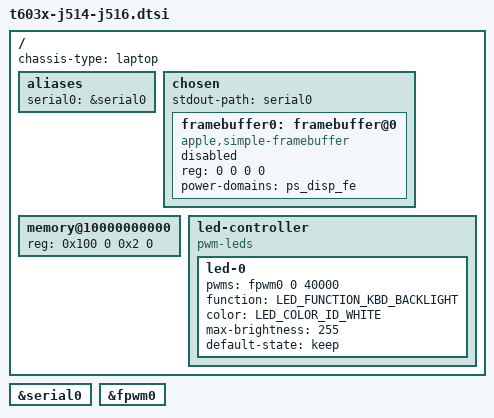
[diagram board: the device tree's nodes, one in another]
// SPDX-License-Identifier: GPL-2.0+ OR MIT
/*
 * MacBook Pro (14/16-inch, 2023)
 *
 * This file contains the parts common to J514 and J516 devices with t6030,
 * t6031 and t6034.
 *
 * target-type: J514s / J514m / J514c / J516s / J516m / J516c
 *
 * Copyright The Asahi Linux Contributors
 */

/*
 * These models are essentially identical to the previous generations, other
 * than the GPIO indices and using SPMI based USB Type-C port controllers.
 */

#include <dt-bindings/leds/common.h>

/ {
	chassis-type = "laptop";

	aliases {
		serial0 = &serial0;
	};

	chosen {
		#address-cells = <2>;
		#size-cells = <2>;
		ranges;

		stdout-path = "serial0";

		framebuffer0: framebuffer@0 {
			compatible = "apple,simple-framebuffer", "simple-framebuffer";
			reg = <0 0 0 0>; /* To be filled by loader */
			/* Format properties will be added by loader */
			status = "disabled";
			power-domains = <&ps_disp_fe>;
		};
	};

	memory@10000000000 {
		device_type = "memory";
		reg = <0x100 0 0x2 0>; /* To be filled by loader */
	};

	led-controller {
		compatible = "pwm-leds";
		led-0 {
			pwms = <&fpwm0 0 40000>;
			function = LED_FUNCTION_KBD_BACKLIGHT;
			color = <LED_COLOR_ID_WHITE>;
			max-brightness = <255>;
			default-state = "keep";
		};
	};
};

&serial0 {
	status = "okay";
};

&fpwm0 {
	status = "okay";
};
